# TLE987x register map
Vendor: Infineon; Series: MOTIX MCU; File version: 4.2
CPU: CM3 r0p0, little endian, no MPU, no FPU, 4 interrupt priority bits
Registers are 32-bit, read-write, reset 0x0 unless marked. A register's access mark holds for its fields unless they carry their own. Offsets are from the block's base; [hi:lo] are bit positions; {n}, {i} and the like mark numbered series; 'fields as' and 'values as' point back to an identical list.

## PORT — GPIO PORTs
Base 0x48028000
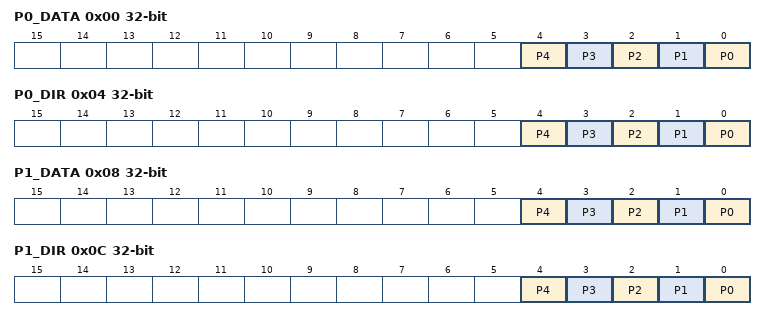
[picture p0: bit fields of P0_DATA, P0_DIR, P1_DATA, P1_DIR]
0x00 P0_DATA reset not defined — Port 0 Data Register
  [all] fields
    0=Port 0 pin n data value = 0; 1=Port 0 pin n data value = 1
  [n] P{n} (n=0..4) — Port 0 Pin {n} Data Value
0x04 P0_DIR — Port 0 Direction Register
  [all] fields
    0=Direction is set to input (default); 1=Direction is set to output
  [n] P{n} (n=0..4) — Port 0 Pin {n} Direction Control
0x08 P1_DATA reset not defined — Port 1 Data Register
  [all] fields
    0=Port 1 pin n data value = 0; 1=Port 1 pin n data value = 1
  [n] P{n} (n=0..4) — Port 1 Pin {n} Data Value
0x0C P1_DIR — Port 1 Direction Register
  [all] fields
    values as the fields of P0_DIR
  [n] P{n} (n=0..4) — Port 1 Pin {n} Direction Control
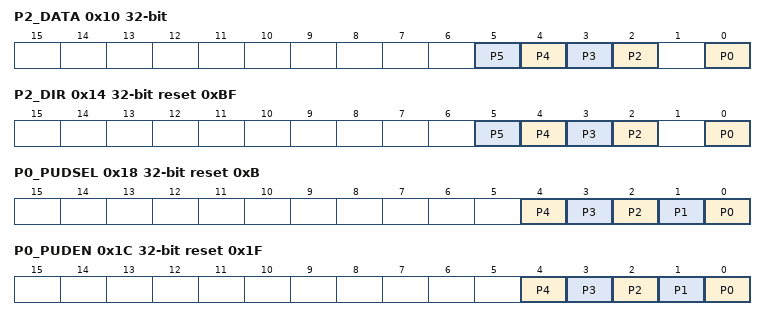
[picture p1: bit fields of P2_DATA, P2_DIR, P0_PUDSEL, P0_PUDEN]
0x10 P2_DATA ro reset not defined — Port 2 Data Register
  [all] fields
    0=Port 2 pin n data value = 0; 1=Port 2 pin n data value = 1
  [n] P{n} (n=2..5) — Port 2 Pin {n} Data Value
  [0] P0 — Port 2 Pin 0 Data Value
0x14 P2_DIR reset 0xBF — Port 2 Direction Register
  [all] fields
    0=Input driver is enabled; 1=Input driver is disabled (default)
  [n] P{n} (n=2..5) — Port 2 Pin {n} Driver Control
  [0] P0 — Port 2 Pin 0 Driver Control
0x18 P0_PUDSEL reset 0xB — Port 0 Pull-Up/Pull-Down Select Register
  [all] fields
    0=Pull-down device is selected; 1=Pull-up device is selected
  [n] P{n} (n=0..4) — Pull-Up/Pull-Down Select Port 0 Bit {n}
0x1C P0_PUDEN reset 0x1F — Port 0 Pull-Up/Pull-Down Enable Register
  [all] fields
    0=Pull-up or Pull-down device is disabled; 1=Pull-up or Pull-down device is enabled
  [n] P{n} (n=0..4) — Pull-Up/Pull-Down Enable at Port 0 Bit {n}
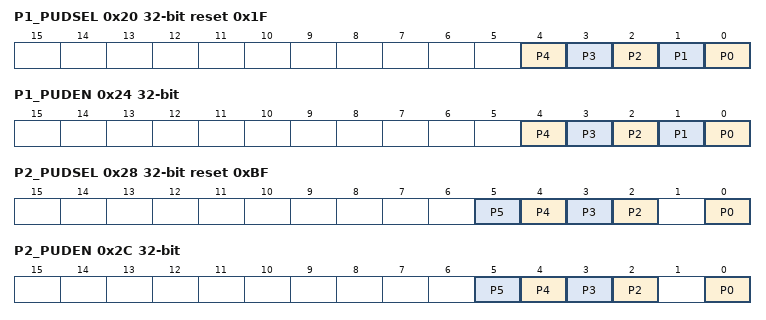
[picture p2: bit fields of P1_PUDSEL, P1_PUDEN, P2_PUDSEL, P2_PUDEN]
0x20 P1_PUDSEL reset 0x1F — Port 1 Pull-Up/Pull-Down Select Register
  [all] fields
    0=Pull-down device is selected; 1=Pull-up device is selected (default)
  [n] P{n} (n=0..4) — Pull-Up/Pull-Down Select Port 1 Bit {n}
0x24 P1_PUDEN — Port 1 Pull-Up/Pull-Down Enable Register
  [all] fields
    0=Pull-up or Pull-down device is disabled (default); 1=Pull-up or Pull-down device is enabled
  [n] P{n} (n=0..4) — Pull-Up/Pull-Down Enable at Port 1 Bit {n}
0x28 P2_PUDSEL reset 0xBF — Port 2 Pull-Up/Pull-Down Select Register
  [all] fields
    values as the fields of P1_PUDSEL
  [n] P{n} (n=2..5) — Pull-Up/Pull-Down Select Port 2 Bit {n}
  [0] P0 — Pull-Up/Pull-Down Select Port 2 Bit 0
0x2C P2_PUDEN — Port 2 Pull-Up/Pull-Down Enable Register
  [all] fields
    values as the fields of P1_PUDEN
  [n] P{n} (n=2..5) — Pull-Up/Pull-Down Enable at Port 2 Bit {n}
  [0] P0 — Pull-Up/Pull-Down Enable at Port 2 Bit 0
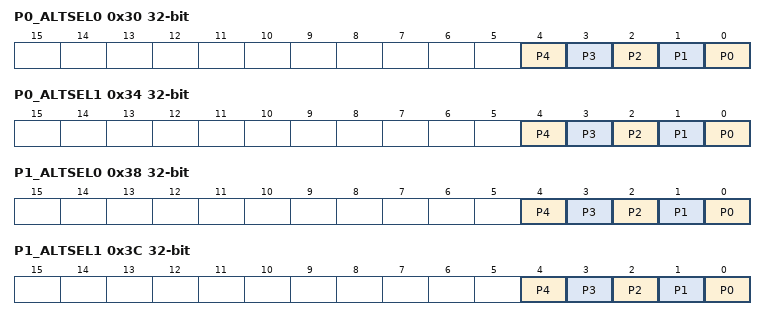
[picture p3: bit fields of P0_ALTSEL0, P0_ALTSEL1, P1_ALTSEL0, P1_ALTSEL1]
0x30 P0_ALTSEL0 — Port 0 Alternate Select Register
  [n] P{n} (n=0..4) — Alternate Select Port 0 Bit {n}
0x34 P0_ALTSEL1 — Port 0 Alternate Select Register
  [n] P{n} (n=0..4) — Alternate Select Port 0 Bit {n}
0x38 P1_ALTSEL0 — Port 1 Alternate Select Register
  [n] P{n} (n=0..4) — Alternate Select Port 1 Bit {n}
0x3C P1_ALTSEL1 — Port 1 Alternate Select Register
  [n] P{n} (n=0..4) — Alternate Select Port 1 Bit {n}
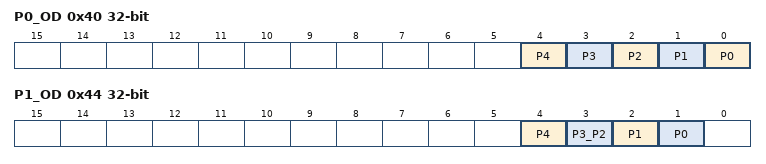
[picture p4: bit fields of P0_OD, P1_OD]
0x40 P0_OD — Port 0 Open Drain Control Register
  [all] fields
    0=Normal Mode, output is actively driven for 0 and 1 state (default); 1=Open Drain Mode, output is actively driven only for 0 state
  [n] P{n} (n=0..4) — Port 0 Pin {n} Open Drain Mode
0x44 P1_OD — Port 1 Open Drain Control Register
  [all] fields
    values as the fields of P0_OD
  [4] P4 — P1.4 Open Drain Mode
  [3] P3_P2 — P1.3/P1.2 Open Drain Mode
  [2] P1 — P1.1 Open Drain Mode
  [1] P0 — P1.0 Open Drain Mode

## SSC1 — SSC1 Module
Base 0x48024000
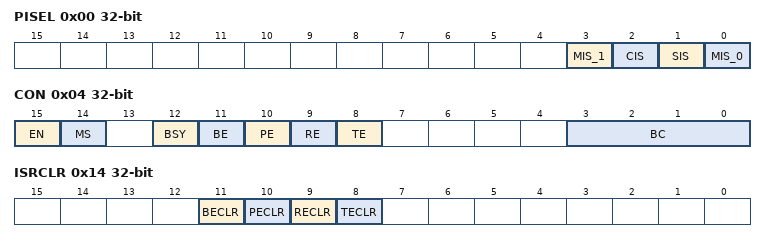
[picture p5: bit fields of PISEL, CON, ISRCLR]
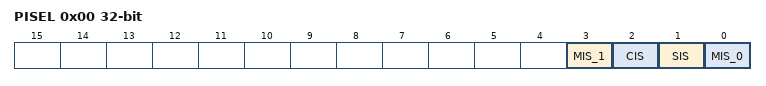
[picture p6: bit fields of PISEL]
0x00 PISEL — Port Input Select Register, RESET_TYPE_3
  [3] MIS_1 — Master Mode Receiver Input Select: 0b0=see (SSC1)., 0b1=see (SSC1)., 0b0=n/a (SSC2)., 0b1=n/a (SSC2).,
  [2] CIS — Slave Mode Clock Input Select: 0b0=Clock input (Port A: P0.3) is selected (SSC1)., 0b1=Clock input (Port B: P0.3) is selected (SSC1)., 0b0=Clock input (Port A: P1.0) is selected (SSC2)., 0b1=Clock input (Port B: P1.0) is selected (SSC2).,
  [1] SIS — Slave Mode Receiver Input Select: 0b0=Receiver input (Port A: P0.2) is selected (SSC1)., 0b1=Receiver input (Port B: P0.2) is selected (SSC1)., 0b0=Receiver input (Port A: P1.1) is selected (SSC2)., 0b1=Receiver input (Port B: P1.1) is selected (SSC2).,
  [0] MIS_0 — Master Mode Receiver Input Select: 0b0=see (SSC1)., 0b1=see (SSC1)., 0b0=Receiver input (Port A: P1.2) is selected (SSC2)., 0b1=Receiver input (Port B: P2.5) is selected (SSC2).,
0x04 CON access per field — Control Register
  [15] EN rw — Enable Bit = 1
  [14] MS rw — Master Select Bit
    0=Slave Mode. Operate on shift clock received via SCLK.; 1=Master Mode. Generate shift clock and output it via SCLK.
  [12] BSY ro — Busy Flag
  [11] BE ro — Baud Rate Error Flag
    0=No error; 1=More than factor 2 or 0.5 between slave's actual and expected baud rate
  [10] PE ro — Phase Error Flag
    0=No error; 1=Received data changes around sampling clock edge
  [9] RE ro — Receive Error Flag
    0=No error; 1=Reception completed before the receive buffer was read
  [8] TE ro — Transmit Error Flag
    0=No error; 1=Transfer starts with the slave's transmit buffer not being updated
  [3:0] BC ro — Bit Count Field
0x08 TB — Transmitter Buffer Register
  [15:0] TB_VALUE — Transmit Data Register Value
0x0C RB ro — Receiver Buffer Register
  [15:0] RB_VALUE — Receive Data Register Value
0x10 BR — Baud Rate Timer Reload Register
  [15:0] BR_VALUE — Baud Rate Timer/Reload Register Value
0x14 ISRCLR wo — Interrupt Status Register Clear
  [all] fields
    0=No error clear; 1=Error clear
  [11] BECLR — Baud Rate Error Flag Clear
  [10] PECLR — Phase Error Flag Clear
  [9] RECLR — Receive Error Flag Clear
  [8] TECLR — Transmit Error Flag Clear

## SSC2 — SSC2 Module
Base 0x48026000
Registers as SSC1; these are added or differ:
0x00 PISEL — Port Input Select Register, RESET_TYPE_3
  fields as SSC1.PISEL
